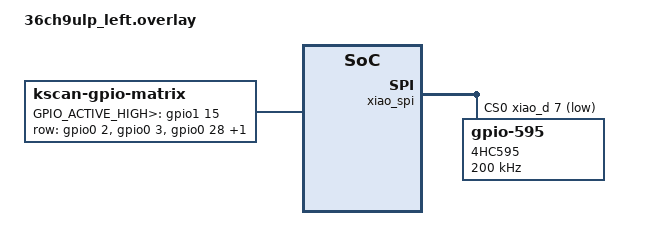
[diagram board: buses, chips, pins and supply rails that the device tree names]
#include "36ch9ulp.dtsi" // Notice that the main dtsi files are included in the overlay.

&xiao_spi {
    status = "okay";
    cs-gpios = <&xiao_d 7 GPIO_ACTIVE_LOW>;
    shifter: 595@0 {
        compatible = "zmk,gpio-595";
        status = "okay";
        gpio-controller;
        spi-max-frequency = <200000>;
        reg = <0>;
        label = "4HC595";
        #gpio-cells = <2>;
        ngpios = <8>;
    };
};

/{
    kscan0: kscan {
        compatible = "zmk,kscan-gpio-matrix";
        label = "KSCAN";
        diode-direction = "col2row";
        // compatible = "zmk,kscan-gpio-matrix";
        // diode-direction = "col2row";
    col-gpios
        , <&gpio1 11 GPIO_ACTIVE_HIGH>//Col4
        , <&gpio1 12 GPIO_ACTIVE_HIGH>//Col3
        , <&gpio1 13 GPIO_ACTIVE_HIGH>//Col2
        , <&gpio1 14 GPIO_ACTIVE_HIGH>//Col1
    	= <&gpio1 15 GPIO_ACTIVE_HIGH>//Col0
        ;
	row-gpios
        = <&gpio0 2 (GPIO_ACTIVE_HIGH | GPIO_PULL_DOWN)>   //Row2
        , <&gpio0 3 (GPIO_ACTIVE_HIGH | GPIO_PULL_DOWN)>   //Row3
        , <&gpio0 28 (GPIO_ACTIVE_HIGH | GPIO_PULL_DOWN)>  //Row0
        , <&gpio0 29 (GPIO_ACTIVE_HIGH | GPIO_PULL_DOWN)>   //Row1
        ;
    };
};
